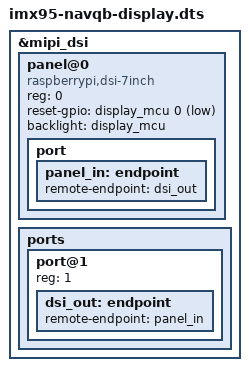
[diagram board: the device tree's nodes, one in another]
// SPDX-License-Identifier: (GPL-2.0+ OR MIT)
/*
 * Copyright 2026 NXP
 */

#include "imx95-navqb.dts"

&mipi_dsi {
	#address-cells = <1>;
	#size-cells = <0>;
	status = "okay";

	panel@0 {
		reg = <0>;
		compatible = "raspberrypi,dsi-7inch";
		reset-gpio = <&display_mcu 0 GPIO_ACTIVE_LOW>;
		backlight = <&display_mcu>;
		status = "okay";

		port {
			panel_in: endpoint {
				remote-endpoint = <&dsi_out>;
			};
		};
	};

	ports {
		#address-cells = <1>;
		#size-cells = <0>;

		port@1 {
			reg = <1>;

			dsi_out: endpoint {
				remote-endpoint = <&panel_in>;
			};
		};
	};
};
